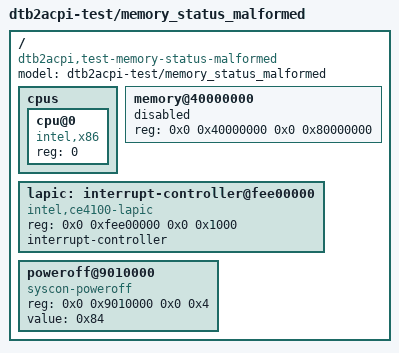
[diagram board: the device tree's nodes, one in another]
/dts-v1/;

/* `status = "bogus"` on a memory node — not one of the DT-spec
 * values. `decode_status(_, Site::Memory)` must reject with
 * MalformedProperty attributed to Site::Memory (distinct from the
 * cpu-side malformed status which reports Site::Cpu).
 */

/ {
	#address-cells = <2>;
	#size-cells = <2>;
	model = "dtb2acpi-test/memory_status_malformed";
	compatible = "dtb2acpi,test-memory-status-malformed";

	cpus {
		#address-cells = <1>;
		#size-cells = <0>;

		cpu@0 {
			device_type = "cpu";
			reg = <0>;
			compatible = "intel,x86";
		};
	};

	memory@40000000 {
		device_type = "memory";
		reg = <0x0 0x40000000 0x0 0x80000000>;
		status = "bogus";
	};

		lapic: interrupt-controller@fee00000 {
		compatible = "intel,ce4100-lapic";
		reg = <0x0 0xfee00000 0x0 0x1000>;
		interrupt-controller;
		#interrupt-cells = <2>;
	};
		poweroff@9010000 {
		compatible = "syscon-poweroff";
		reg = <0x0 0x9010000 0x0 0x4>;
		value = <0x84>;
	};
};
